# RN821X_RN721X_SOC_V2 register map
File version: v1.0.7
CPU: CM0 r0p0, little endian, no MPU, no FPU, 3 interrupt priority bits
Registers are 32-bit, read-write, reset 0x0 unless marked. A register's access mark holds for its fields unless they carry their own. Offsets are from the block's base; [hi:lo] are bit positions; {n}, {i} and the like mark numbered series.

## FLK — Flicker calculation module
Base 0x50020000
0x00 EN reset not defined — Flicker module enable register
  [0] EN — Flicker module enable bit
0x04 IE reset not defined — Flicker module interrupt enable register
  [0] IE — Flicker module interrupt enable bit
0x08 IF reset not defined — Flicker module interrupt flag register
  [0] IF — Flicker module interrupt sign bit
0x0C UA_600HZ 24-bit ro reset not defined — UA channel instantaneous sampling value (600hz update) register
  [23:0] UA_600HZ — UA channel instantaneous sampling value (600hz update) bits
0x10 PASS 16-bit wo reset not defined — Flicker module password register
  [15:0] PASS — Flicker module password bits
    0=DIS (Flicker module password disable); 0x2025=PASS (Flicker module password enable)

## I2C — I2C controller
Base 0x40024000
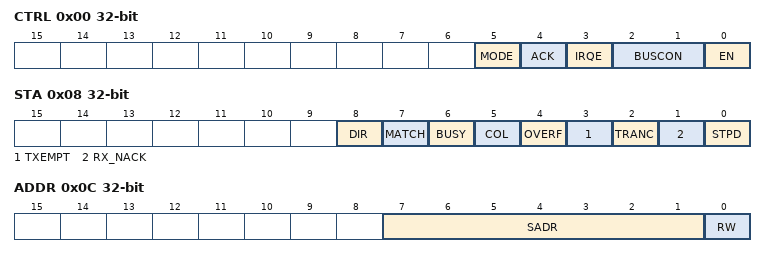
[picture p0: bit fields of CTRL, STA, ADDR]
0x00 CTRL — I2C control register
  [5] MODE — I2C slave/master mode selection bit
    0=S (select as slave device); 1=M (select as master device)
  [4] ACK — ACK signal configuration bit
    1=ACK (receive 9st SCL generate ACK); 0=NUL (receive 9st SCL donot generate ACK)
  [3] IRQE — I2C interrupt enable bit
  [2:1] BUSCON — I2C bus control bit (when finish command transmision clear automatically)
    0=NUL (no action); 1=START (generate start sequence (clear automatically when finish command transmision)); 2=STOP (generate stop sequence (clear automatically when finish command transmision))
  [0] EN — I2C module enable bit
0x04 CLK reset 0x1 — I2C clock configuration register
  [2:0] CLKDIV — I2C module clock divisor selection bits
    1=DEFAULT (select I2C module clock divisor as 10); 2=7M4_FM (when system clock = 7.3728Mhz, select I2C as fast speed mode, module clock set at system clock divided by 20); 3=14M7_FM (when system clock = 14.7456Mhz, select I2C as fast speed mode, module clock set at system clock divided by 38); 4=29M5_FM (when system clock = 29.4912Mhz, select I2C as fast speed mode, module clock set at system clock divided by 76); 2=1M8_SM (when system clock = 1.8432Mhz , select I2C as standard speed mode, module clock set at system clock divided by 20); 3=3M6_SM (when system clock = 3.6864Mhz , select I2C as standard speed mode, module clock set at system clock divided by 38); 4=7M4_SM (when system clock = 7.3728Mhz , select I2C as standard speed mode, module clock set at system clock divided by 76); 5=14M7_SM (when system clock = 14.7456Mhz, select I2C as standard speed mode, module clock set at system clock divided by 154); 6=29M5_SM (when system clock = 29.4912Mhz, select I2C as standard speed mode, module clock set at system clock divided by 306)
0x08 STA — I2C status indicate register
  [8] DIR ro — receive/transmit direction flag
    0=T (device as transmitting status); 1=R (device as receiving status)
  [7] MATCH ro — address match flag
  [6] BUSY ro — communication busy flag
  [5] COL write-1-clears — interrupt flag of transmit conflict
  [4] OVERF write-1-clears — interrupt flag of receive data overflow
  [3] TXEMPT write-1-clears — transmit data registor empty error flag
  [2] TRANC write-1-clears — interrupt flag of transmit finish
  [1] RX_NACK write-1-clears — interrupt flag of receive NACK interrupt
  [0] STPD write-1-clears — interrupt flag of stop time sequence detection
0x0C ADDR — I2C slave device address register
  [7:1] SADR — device address configuration bits
  [0] RW — receive/transmit direction configuration bit
    0=T (configuration as transmit device); 1=R (configuration as receive device)
0x10 DATA — I2C data transmit/receive register
  [7:0] DATA — I2C transfer data bits

## INTC — interrupt controller for off-chip interrupt requests
Base 0x40044000
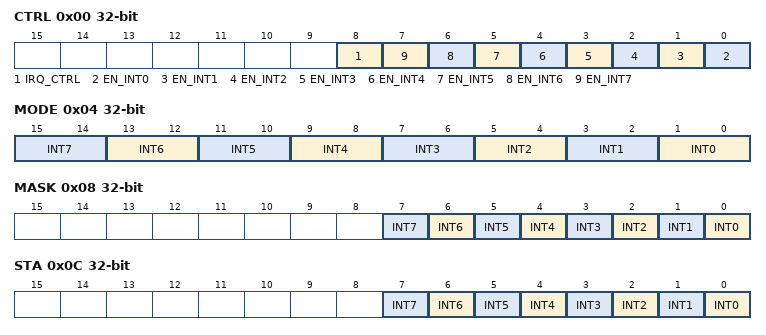
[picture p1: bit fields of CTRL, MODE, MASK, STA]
0x00 CTRL — INTC control register
  [8] IRQ_CTRL — external interrupt mode selection bit
    0=INDEP (INT0~INT7 independent control by INTC_CTRL[7:0]); 1=EXT0 (INT0~INT7 share EXT0 IRQ vector, check STA while interrupt occured)
  [n] EN_INT{n} (n=0..7) — external interrupt INT{n} module enable bit
0x04 MODE — INTC mode register
  [2n+1:2n] INT{n} (n=0..7) — external interrupt INT{n} mode selection bit
    0=PE (external interrupt INT{n} mode selection as posedge mode); 1=NE (external interrupt INT{n} mode selection as negedge mode); 2=BE (external interrupt INT{n} mode selection as both edge mode)
0x08 MASK — INTC mask register
  [n] INT{n} (n=0..7) — external interrupt INT{n} interrupt enable/disable bit
    0=DIS (external interrupt INT{n} interrupt disable); 1=EN (external interrupt INT{n} interrupt enable)
0x0C STA — Extern interrupt status register
  [all] fields
    0=NUL (external interrupt event not occured); 1=OCC (external interrupt event occured)
  [n] INT{n} write-1-clears (n=0..7) — external interrupt INT{n} status bit
